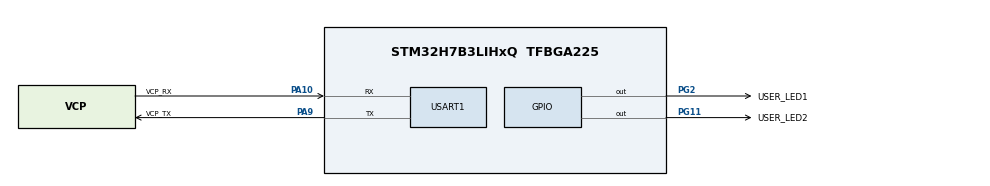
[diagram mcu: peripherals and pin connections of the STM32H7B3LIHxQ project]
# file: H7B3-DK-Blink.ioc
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Mcu.Family=STM32H7
Mcu.Name=STM32H7B3LIHxQ
Mcu.Package=TFBGA225
NVIC.PriorityGroup=NVIC_PRIORITYGROUP_4
PA10.GPIO_Label=VCP_RX
PA10.Mode=Asynchronous
PA10.Signal=USART1_RX
PA13.Mode=JTAG_5_pins
PA13.Signal=DEBUG_JTMS-SWDIO
PA14.Mode=JTAG_5_pins
PA14.Signal=DEBUG_JTCK-SWCLK
PA15.Mode=JTAG_5_pins
PA15.Signal=DEBUG_JTDI
PA9.GPIO_Label=VCP_TX
PA9.Mode=Asynchronous
PA9.Signal=USART1_TX
PB3.Mode=JTAG_5_pins
PB3.Signal=DEBUG_JTDO-SWO
PB4.Mode=JTAG_5_pins
PB4.Signal=DEBUG_JTRST
PC14-OSC32_IN.Mode=LSE-External-Oscillator
PC14-OSC32_IN.Signal=RCC_OSC32_IN
PC15-OSC32_OUT.Mode=LSE-External-Oscillator
PC15-OSC32_OUT.Signal=RCC_OSC32_OUT
PG11.GPIO_Label=USER_LED2
PG11.Signal=GPIO_Output
PG2.GPIO_Label=USER_LED1
PG2.Signal=GPIO_Output
PH0-OSC_IN.Mode=HSE-External-Oscillator
PH0-OSC_IN.Signal=RCC_OSC_IN
PH1-OSC_OUT.Mode=HSE-External-Oscillator
PH1-OSC_OUT.Signal=RCC_OSC_OUT
ProjectManager.HeapSize=0x200
ProjectManager.StackSize=0x400
ProjectManager.TargetToolchain=STM32CubeIDE
RCC.ADCFreq_Value=48375000
RCC.APB1Freq_Value=32000000
RCC.APB2Freq_Value=32000000
RCC.APB3Freq_Value=32000000
RCC.APB4Freq_Value=32000000
RCC.CDPPRE=RCC_APB3_DIV2
RCC.CDPPRE1=RCC_APB1_DIV2
RCC.CDPPRE2=RCC_APB2_DIV2
RCC.CortexFreq_Value=64000000
RCC.DIVM1=2
RCC.DIVN1=32
RCC.DIVP1=6
RCC.HCLKFreq_Value=64000000
RCC.PLL2FRACN=0
RCC.PLL3FRACN=0
RCC.PLLFRACN=0
RCC.PLLSourceVirtual=RCC_PLLSOURCE_HSE
RCC.SRDPPRE=RCC_APB4_DIV2
RCC.SYSCLKFreq_VALUE=64000000
RCC.SYSCLKSource=RCC_SYSCLKSOURCE_PLLCLK
RCC.USBFreq_Value=192000000
USART1.VirtualMode-Asynchronous=VM_ASYNC
board=custom

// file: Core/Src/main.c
/* USER CODE BEGIN Header */
/**
  ******************************************************************************
  * @file           : main.c
  * @brief          : Main program body
  ******************************************************************************
  * @attention
  *
  * <h2><center>&copy; Copyright (c) 2020 STMicroelectronics.
  * All rights reserved.</center></h2>
  *
  * This software component is licensed by ST under BSD 3-Clause license,
  * the "License"; You may not use this file except in compliance with the
  * License. You may obtain a copy of the License at:
  *                        opensource.org/licenses/BSD-3-Clause
  *
  ******************************************************************************
  */
/* USER CODE END Header */
#include "main.h"

void SystemClock_Config(void);
static void MX_GPIO_Init(void);
static void MX_USART1_UART_Init(void);

int main(void)
{

  /* MCU Configuration--------------------------------------------------------*/

  /* Reset of all peripherals, Initializes the Flash interface and the Systick. */

  LL_APB4_GRP1_EnableClock(LL_APB4_GRP1_PERIPH_SYSCFG);

  NVIC_SetPriorityGrouping(NVIC_PRIORITYGROUP_4);

  /* System interrupt init*/

  /* Configure the system clock */
  SystemClock_Config();

  /* Initialize all configured peripherals */
  MX_GPIO_Init();
  MX_USART1_UART_Init();

  /* Infinite loop */
  while (1)
  {

    /* USER CODE BEGIN 3 */
	  LL_GPIO_TogglePin(USER_LED1_GPIO_Port, USER_LED2_Pin);
	  for(int i=0; i<4; i++)
	  {
		  LL_GPIO_TogglePin(USER_LED1_GPIO_Port, USER_LED1_Pin);
		  /* Insert delay 250 ms */
		  LL_mDelay(250);
	  }

  }
  /* USER CODE END 3 */
}

void SystemClock_Config(void)
{
  LL_FLASH_SetLatency(LL_FLASH_LATENCY_2);
  while(LL_FLASH_GetLatency()!= LL_FLASH_LATENCY_2)
  {
  }
  LL_PWR_ConfigSupply(LL_PWR_LDO_SUPPLY);
  LL_PWR_SetRegulVoltageScaling(LL_PWR_REGU_VOLTAGE_SCALE3);
  LL_RCC_HSE_Enable();

   /* Wait till HSE is ready */
  while(LL_RCC_HSE_IsReady() != 1)
  {

  }
  LL_RCC_PLL_SetSource(LL_RCC_PLLSOURCE_HSE);
  LL_RCC_PLL1P_Enable();
  LL_RCC_PLL1R_Enable();
  LL_RCC_PLL1_SetVCOInputRange(LL_RCC_PLLINPUTRANGE_8_16);
  LL_RCC_PLL1_SetVCOOutputRange(LL_RCC_PLLVCORANGE_WIDE);
  LL_RCC_PLL1_SetM(2);
  LL_RCC_PLL1_SetN(32);
  LL_RCC_PLL1_SetP(6);
  LL_RCC_PLL1_SetQ(2);
  LL_RCC_PLL1_SetR(2);
  LL_RCC_PLL1_Enable();

   /* Wait till PLL is ready */
  while(LL_RCC_PLL1_IsReady() != 1)
  {
  }

  LL_RCC_SetSysClkSource(LL_RCC_SYS_CLKSOURCE_PLL1);
  LL_RCC_SetAHBPrescaler(LL_RCC_AHB_DIV_1);
  LL_RCC_SetAPB1Prescaler(LL_RCC_APB1_DIV_2);
  LL_RCC_SetAPB2Prescaler(LL_RCC_APB2_DIV_2);
  LL_RCC_SetAPB3Prescaler(LL_RCC_APB3_DIV_2);
  LL_RCC_SetAPB4Prescaler(LL_RCC_APB4_DIV_2);

  LL_Init1msTick(64000000);

  LL_SetSystemCoreClock(64000000);
  LL_RCC_SetUSARTClockSource(LL_RCC_USART16_CLKSOURCE_PCLK2);
}

static void MX_USART1_UART_Init(void)
{

  LL_USART_InitTypeDef USART_InitStruct = {0};

  LL_GPIO_InitTypeDef GPIO_InitStruct = {0};

  /* Peripheral clock enable */
  LL_APB2_GRP1_EnableClock(LL_APB2_GRP1_PERIPH_USART1);

  LL_AHB4_GRP1_EnableClock(LL_AHB4_GRP1_PERIPH_GPIOA);
  /**USART1 GPIO Configuration
  PA10   ------> USART1_RX
  PA9   ------> USART1_TX
  */
  GPIO_InitStruct.Pin = VCP_RX_Pin|VCP_TX_Pin;
  GPIO_InitStruct.Mode = LL_GPIO_MODE_ALTERNATE;
  GPIO_InitStruct.Speed = LL_GPIO_SPEED_FREQ_LOW;
  GPIO_InitStruct.OutputType = LL_GPIO_OUTPUT_PUSHPULL;
  GPIO_InitStruct.Pull = LL_GPIO_PULL_NO;
  GPIO_InitStruct.Alternate = LL_GPIO_AF_7;
  LL_GPIO_Init(GPIOA, &GPIO_InitStruct);

  USART_InitStruct.PrescalerValue = LL_USART_PRESCALER_DIV1;
  USART_InitStruct.BaudRate = 115200;
  USART_InitStruct.DataWidth = LL_USART_DATAWIDTH_8B;
  USART_InitStruct.StopBits = LL_USART_STOPBITS_1;
  USART_InitStruct.Parity = LL_USART_PARITY_NONE;
  USART_InitStruct.TransferDirection = LL_USART_DIRECTION_TX_RX;
  USART_InitStruct.HardwareFlowControl = LL_USART_HWCONTROL_NONE;
  USART_InitStruct.OverSampling = LL_USART_OVERSAMPLING_16;
  LL_USART_Init(USART1, &USART_InitStruct);
  LL_USART_SetTXFIFOThreshold(USART1, LL_USART_FIFOTHRESHOLD_1_8);
  LL_USART_SetRXFIFOThreshold(USART1, LL_USART_FIFOTHRESHOLD_1_8);
  LL_USART_DisableFIFO(USART1);
  LL_USART_ConfigAsyncMode(USART1);

  LL_USART_Enable(USART1);

  /* Polling USART1 initialisation */
  while((!(LL_USART_IsActiveFlag_TEACK(USART1))) || (!(LL_USART_IsActiveFlag_REACK(USART1))))
  {
  }

}

static void MX_GPIO_Init(void)
{
  LL_GPIO_InitTypeDef GPIO_InitStruct = {0};

  /* GPIO Ports Clock Enable */
  LL_AHB4_GRP1_EnableClock(LL_AHB4_GRP1_PERIPH_GPIOB);
  LL_AHB4_GRP1_EnableClock(LL_AHB4_GRP1_PERIPH_GPIOG);
  LL_AHB4_GRP1_EnableClock(LL_AHB4_GRP1_PERIPH_GPIOA);
  LL_AHB4_GRP1_EnableClock(LL_AHB4_GRP1_PERIPH_GPIOC);
  LL_AHB4_GRP1_EnableClock(LL_AHB4_GRP1_PERIPH_GPIOH);

  /**/
  LL_GPIO_ResetOutputPin(GPIOG, USER_LED2_Pin|USER_LED1_Pin);

  /**/
  GPIO_InitStruct.Pin = USER_LED2_Pin|USER_LED1_Pin;
  GPIO_InitStruct.Mode = LL_GPIO_MODE_OUTPUT;
  GPIO_InitStruct.Speed = LL_GPIO_SPEED_FREQ_LOW;
  GPIO_InitStruct.OutputType = LL_GPIO_OUTPUT_PUSHPULL;
  GPIO_InitStruct.Pull = LL_GPIO_PULL_NO;
  LL_GPIO_Init(GPIOG, &GPIO_InitStruct);

}

void Error_Handler(void)
{
}

/************************ (C) COPYRIGHT STMicroelectronics *****END OF FILE****/
